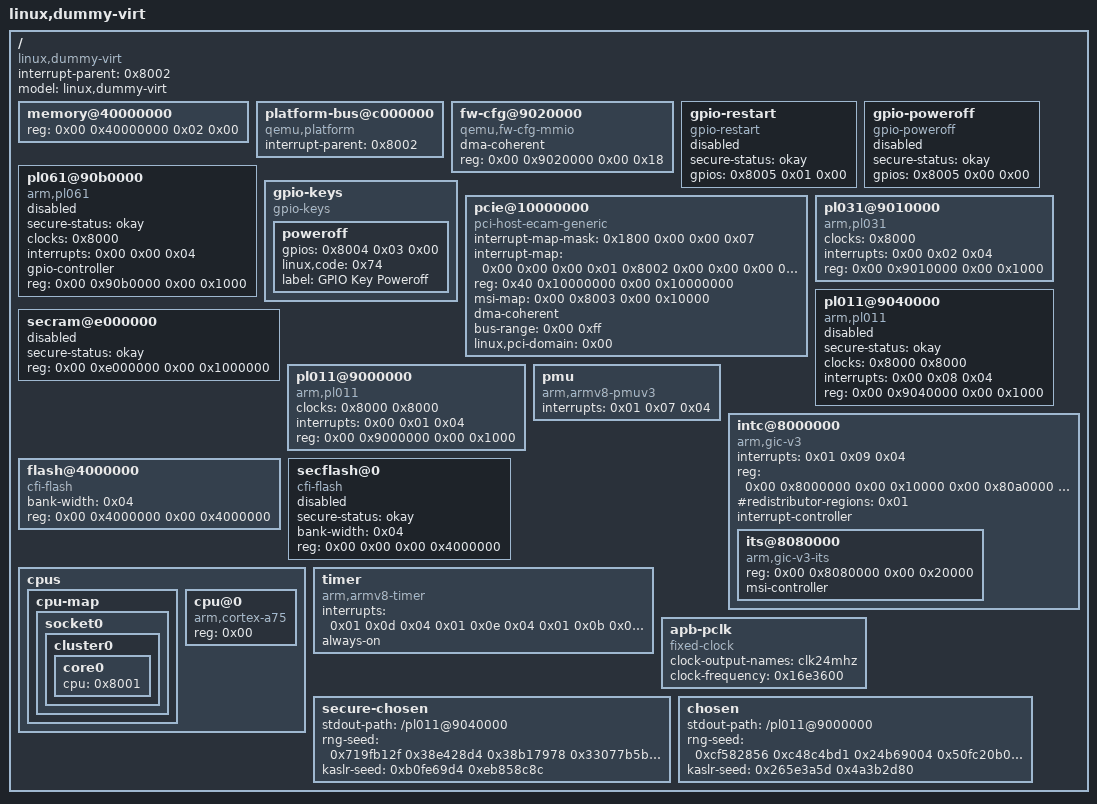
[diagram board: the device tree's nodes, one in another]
/dts-v1/;

/ {
	interrupt-parent = <0x8002>;
	model = "linux,dummy-virt";
	#size-cells = <0x02>;
	#address-cells = <0x02>;
	compatible = "linux,dummy-virt";

	memory@40000000 {
		reg = <0x00 0x40000000 0x02 0x00>;
		device_type = "memory";
	};

	platform-bus@c000000 {
		interrupt-parent = <0x8002>;
		ranges = <0x00 0x00 0xc000000 0x2000000>;
		#address-cells = <0x01>;
		#size-cells = <0x01>;
		compatible = "qemu,platform\0simple-bus";
	};

	fw-cfg@9020000 {
		dma-coherent;
		reg = <0x00 0x9020000 0x00 0x18>;
		compatible = "qemu,fw-cfg-mmio";
	};

	gpio-restart {
		secure-status = "okay";
		status = "disabled";
		gpios = <0x8005 0x01 0x00>;
		compatible = "gpio-restart";
	};

	gpio-poweroff {
		secure-status = "okay";
		status = "disabled";
		gpios = <0x8005 0x00 0x00>;
		compatible = "gpio-poweroff";
	};

	pl061@90b0000 {
		secure-status = "okay";
		status = "disabled";
		phandle = <0x8005>;
		clock-names = "apb_pclk";
		clocks = <0x8000>;
		interrupts = <0x00 0x00 0x04>;
		gpio-controller;
		#gpio-cells = <0x02>;
		compatible = "arm,pl061\0arm,primecell";
		reg = <0x00 0x90b0000 0x00 0x1000>;
	};

	gpio-keys {
		compatible = "gpio-keys";

		poweroff {
			gpios = <0x8004 0x03 0x00>;
			linux,code = <0x74>;
			label = "GPIO Key Poweroff";
		};
	};

	pcie@10000000 {
		interrupt-map-mask = <0x1800 0x00 0x00 0x07>;
		interrupt-map = <0x00 0x00 0x00 0x01 0x8002 0x00 0x00 0x00 0x03 0x04 0x00 0x00 0x00 0x02 0x8002 0x00 0x00 0x00 0x04 0x04 0x00 0x00 0x00 0x03 0x8002 0x00 0x00 0x00 0x05 0x04 0x00 0x00 0x00 0x04 0x8002 0x00 0x00 0x00 0x06 0x04 0x800 0x00 0x00 0x01 0x8002 0x00 0x00 0x00 0x04 0x04 0x800 0x00 0x00 0x02 0x8002 0x00 0x00 0x00 0x05 0x04 0x800 0x00 0x00 0x03 0x8002 0x00 0x00 0x00 0x06 0x04 0x800 0x00 0x00 0x04 0x8002 0x00 0x00 0x00 0x03 0x04 0x1000 0x00 0x00 0x01 0x8002 0x00 0x00 0x00 0x05 0x04 0x1000 0x00 0x00 0x02 0x8002 0x00 0x00 0x00 0x06 0x04 0x1000 0x00 0x00 0x03 0x8002 0x00 0x00 0x00 0x03 0x04 0x1000 0x00 0x00 0x04 0x8002 0x00 0x00 0x00 0x04 0x04 0x1800 0x00 0x00 0x01 0x8002 0x00 0x00 0x00 0x06 0x04 0x1800 0x00 0x00 0x02 0x8002 0x00 0x00 0x00 0x03 0x04 0x1800 0x00 0x00 0x03 0x8002 0x00 0x00 0x00 0x04 0x04 0x1800 0x00 0x00 0x04 0x8002 0x00 0x00 0x00 0x05 0x04>;
		#interrupt-cells = <0x01>;
		ranges = <0x1000000 0x00 0x00 0x00 0x3eff0000 0x00 0x10000 0x2000000 0x00 0x10000000 0x00 0x10000000 0x00 0x2eff0000 0x3000000 0x80 0x00 0x80 0x00 0x80 0x00>;
		reg = <0x40 0x10000000 0x00 0x10000000>;
		msi-map = <0x00 0x8003 0x00 0x10000>;
		dma-coherent;
		bus-range = <0x00 0xff>;
		linux,pci-domain = <0x00>;
		#size-cells = <0x02>;
		#address-cells = <0x03>;
		device_type = "pci";
		compatible = "pci-host-ecam-generic";
	};

	pl031@9010000 {
		clock-names = "apb_pclk";
		clocks = <0x8000>;
		interrupts = <0x00 0x02 0x04>;
		reg = <0x00 0x9010000 0x00 0x1000>;
		compatible = "arm,pl031\0arm,primecell";
	};

	pl011@9040000 {
		secure-status = "okay";
		status = "disabled";
		clock-names = "uartclk\0apb_pclk";
		clocks = <0x8000 0x8000>;
		interrupts = <0x00 0x08 0x04>;
		reg = <0x00 0x9040000 0x00 0x1000>;
		compatible = "arm,pl011\0arm,primecell";
	};

	secram@e000000 {
		secure-status = "okay";
		status = "disabled";
		reg = <0x00 0xe000000 0x00 0x1000000>;
		device_type = "memory";
	};

	pl011@9000000 {
		clock-names = "uartclk\0apb_pclk";
		clocks = <0x8000 0x8000>;
		interrupts = <0x00 0x01 0x04>;
		reg = <0x00 0x9000000 0x00 0x1000>;
		compatible = "arm,pl011\0arm,primecell";
	};

	pmu {
		interrupts = <0x01 0x07 0x04>;
		compatible = "arm,armv8-pmuv3";
	};

	intc@8000000 {
		phandle = <0x8002>;
		interrupts = <0x01 0x09 0x04>;
		reg = <0x00 0x8000000 0x00 0x10000 0x00 0x80a0000 0x00 0xf60000>;
		#redistributor-regions = <0x01>;
		compatible = "arm,gic-v3";
		ranges;
		#size-cells = <0x02>;
		#address-cells = <0x02>;
		interrupt-controller;
		#interrupt-cells = <0x03>;

		its@8080000 {
			phandle = <0x8003>;
			reg = <0x00 0x8080000 0x00 0x20000>;
			#msi-cells = <0x01>;
			msi-controller;
			compatible = "arm,gic-v3-its";
		};
	};

	flash@4000000 {
		bank-width = <0x04>;
		reg = <0x00 0x4000000 0x00 0x4000000>;
		compatible = "cfi-flash";
	};

	secflash@0 {
		secure-status = "okay";
		status = "disabled";
		bank-width = <0x04>;
		reg = <0x00 0x00 0x00 0x4000000>;
		compatible = "cfi-flash";
	};

	cpus {
		#size-cells = <0x00>;
		#address-cells = <0x01>;

		cpu-map {

			socket0 {

				cluster0 {

					core0 {
						cpu = <0x8001>;
					};
				};
			};
		};

		cpu@0 {
			phandle = <0x8001>;
			reg = <0x00>;
			compatible = "arm,cortex-a75";
			device_type = "cpu";
		};
	};

	timer {
		interrupts = <0x01 0x0d 0x04 0x01 0x0e 0x04 0x01 0x0b 0x04 0x01 0x0a 0x04>;
		always-on;
		compatible = "arm,armv8-timer\0arm,armv7-timer";
	};

	apb-pclk {
		phandle = <0x8000>;
		clock-output-names = "clk24mhz";
		clock-frequency = <0x16e3600>;
		#clock-cells = <0x00>;
		compatible = "fixed-clock";
	};

	secure-chosen {
		stdout-path = "/pl011@9040000";
		rng-seed = <0x719fb12f 0x38e428d4 0x38b17978 0x33077b5b 0x60c50f37 0x1d911284 0x2b7b0e99 0x4dbad519>;
		kaslr-seed = <0xb0fe69d4 0xeb858c8c>;
	};

	chosen {
		stdout-path = "/pl011@9000000";
		rng-seed = <0xcf582856 0xc48c4bd1 0x24b69004 0x50fc20b0 0x3c1c5a6c 0xd159d644 0x1743c73a 0x3a84c5aa>;
		kaslr-seed = <0x265e3a5d 0x4a3b2d80>;
	};
};
